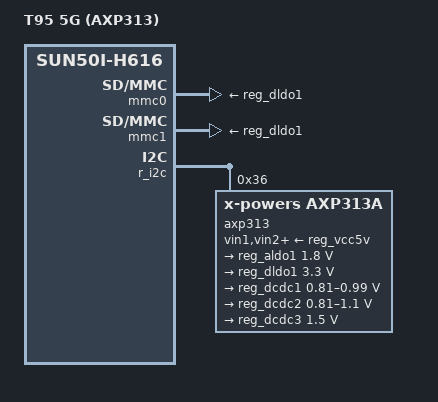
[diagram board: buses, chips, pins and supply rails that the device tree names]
// SPDX-License-Identifier: (GPL-2.0+ OR MIT)
/*
 * Copyright (C) 2024 Kamil Kasperski <ressetkk@gmail.com>
 *
 * Configuration for T95 TV box with board label H616-T95MAX-AXP313A-v3.0
 */

/dts-v1/;

#include "sun50i-h616-t95.dtsi"

/ {
	model = "T95 5G (AXP313)";
	compatible = "t95,t95max-axp313", "allwinner,sun50i-h616";
};

&mmc0 {
	vmmc-supply = <&reg_dldo1>;
};

&mmc1 {
	vmmc-supply = <&reg_dldo1>;
	vqmmc-supply = <&reg_aldo1>;
};

&r_i2c {
	status = "okay";

	axp313: pmic@36 {
		compatible = "x-powers,axp313a";
		reg = <0x36>;
		#interrupt-cells = <1>;
		interrupt-controller;
		interrupt-parent = <&pio>;

		vin1-supply = <&reg_vcc5v>;
		vin2-supply = <&reg_vcc5v>;
		vin3-supply = <&reg_vcc5v>;

		regulators {
			reg_aldo1: aldo1 {
				regulator-always-on;
				regulator-min-microvolt = <1800000>;
				regulator-max-microvolt = <1800000>;
				regulator-name = "vcc1v8";
			};

			reg_dldo1: dldo1 {
				regulator-always-on;
				regulator-min-microvolt = <3300000>;
				regulator-max-microvolt = <3300000>;
				regulator-name = "vcc3v3";
			};

			reg_dcdc1: dcdc1 {
				regulator-always-on;
				regulator-min-microvolt = <810000>;
				regulator-max-microvolt = <990000>;
				regulator-name = "vdd-gpu-sys";
			};

			reg_dcdc2: dcdc2 {
				regulator-always-on;
				regulator-min-microvolt = <810000>;
				regulator-max-microvolt = <1100000>;
				regulator-name = "vdd-cpu";
			};

			reg_dcdc3: dcdc3 {
				regulator-always-on;
				regulator-min-microvolt = <1500000>;
				regulator-max-microvolt = <1500000>;
				regulator-name = "vdd-dram";
			};
		};
	};
};

&pio {
	vcc-pc-supply = <&reg_aldo1>;
	vcc-pf-supply = <&reg_dldo1>;
	vcc-pg-supply = <&reg_dldo1>;
	vcc-ph-supply = <&reg_dldo1>;
	vcc-pi-supply = <&reg_dldo1>;
};
